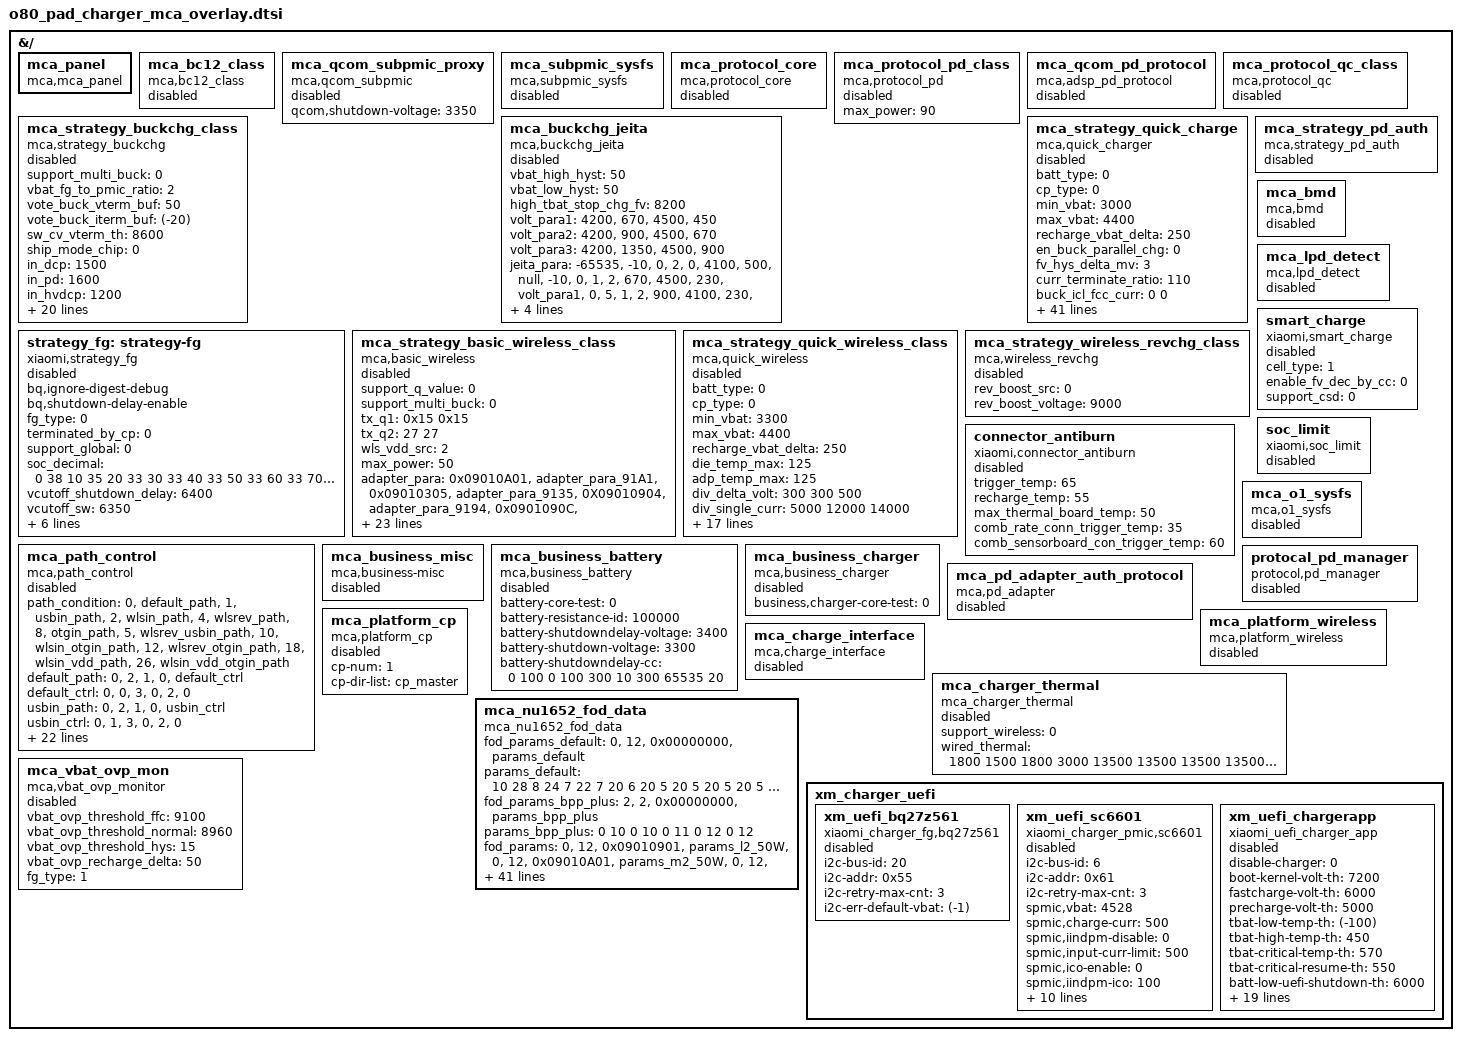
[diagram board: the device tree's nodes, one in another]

&{/} {
	/*	sc8585 dts
	sc8585_master@6e {
		compatible = "sc8585_master";
		status = "disabled";
		ic_role = <0>;
		reg = <0x6e>;
		cp-int= <&dw_gpio1 15 0>; //gpio47
		cp-nlpm-gpio = <&dw_gpio3 26 0>;//gpio 107
		pinctrl-names = "default";
		pinctrl-0 = <&gpio_047_default>,
					<&gpio_107_default>; //gpio107
		pinctrl-1 = <&gpio_212_default>; //212
		bat-ovp-threshold = <4650>;
		bat-ovp-alarm-threshold = <4600>;
		bus-ovp-threshold = <21000 11000 6000>;
		usb-ovp-threshold = <21000 14000 6500>;
		bus-ocp-threshold = <4500 5000 4500>;
		wpc-ovp-threshold = <21000>;
		out-ovp-threshold = <5000>;
		pmid2-uvp-threshold = <100>;
		pmid2-ovp-threshold = <600>;
	};

	// sc8577 dts
	sc8577@65 {
		compatible = "sc8577_master";
		status = "okay";
		ic_role = <0>;
		reg = <0x65>;
		cp-int= <&dw_gpio0 15 0>; //gpio15
		cp-nlpm-gpio = <&dw_gpio3 26 0>;//gpio 107
		pinctrl-names = "default";
		pinctrl-0 = <&gpio_015_default>,
					<&gpio_107_default>,
					<&gpio_212_default>; //gpio212	ovpmos gpio
		bat-ovp-threshold = <9300>;
		bat-ovp-alarm-threshold = <9200>;
		bus-ovp-threshold = <21000 11000>;
		usb-ovp-threshold = <21000 13000>;
		bus-ocp-threshold = <6000 6000>;
		wpc-ovp-threshold = <21000>;
		out-ovp-threshold = <10000>;
		pmid2-uvp-threshold = <100>;
		pmid2-ovp-threshold = <600>;
	};
	 */
	mca_panel: mca_panel {
		compatible = "mca,mca_panel";
		status = "okay";
	};

	mca_bc12_class: mca_bc12_class {
		compatible = "mca,bc12_class";
		status = "disabled";
	};

	mca_qcom_subpmic_proxy: mca_qcom_subpmic_proxy {
		compatible = "mca,qcom_subpmic";
		qcom,shutdown-voltage = <3350>;
		status = "disabled";
	};

	mca_subpmic_sysfs: mca_subpmic_sysfs {
		compatible = "mca,subpmic_sysfs";
		status = "disabled";
	};

	mca_protocol_core: mca_protocol_core {
		compatible = "mca,protocol_core";
		status = "disabled";
	};

	mca_protocol_pd_class: mca_protocol_pd_class {
		compatible = "mca,protocol_pd";
		status = "disabled";
		max_power = <90>;
	};

	mca_qcom_pd_protocol: mca_qcom_pd_protocol {
		compatible = "mca,adsp_pd_protocol";
		status = "disabled";
	};

	mca_protocol_qc_class: mca_protocol_qc_class {
		compatible = "mca,protocol_qc";
		status = "disabled";
	};

	mca_buckchg_jeita: mca_buckchg_jeita {
		compatible = "mca,buckchg_jeita";
		vbat_high_hyst = <50>;
		vbat_low_hyst = <50>;
		high_tbat_stop_chg_fv = <8200>;
		volt_para1 =
			"4200", "670",
			"4500", "450";
		volt_para2 =
			"4200", "900",
			"4500", "670";
		volt_para3 =
			"4200", "1350",
			"4500", "900";
		/* temp_low, temp_high, low_temp_hys, high_temp_hys, max_current, vterm, iterm volt_para_name */
		jeita_para =
			"-65535", "-10", "0", "2", "0", "4100", "500", "null",
			"-10", "0", "1", "2", "670", "4500", "230", "volt_para1",
			"0", "5", "1", "2", "900", "4100", "230", "volt_para2",
			"5", "10", "1", "2", "1350", "4500", "500", "volt_para3",
			"10", "48", "2", "2", "4000", "4500", "230", "null",
			"48", "60", "2", "2", "2250", "4100", "230", "null" ,
			"60", "65535", "2", "2", "0", "4100", "230", "null";

		status = "disabled";
	};

	mca_strategy_buckchg_class: mca_strategy_buckchg_class {
		compatible = "mca,strategy_buckchg";
		support_multi_buck = <0>;
		vbat_fg_to_pmic_ratio = <2>;
		vote_buck_vterm_buf = <50>;
		vote_buck_iterm_buf = <(-20)>;
		sw_cv_vterm_th = <8600>;
		ship_mode_chip = <0>;	/* 0:MAIN_BUCK_CHARGER, 1:AUX_BUCK_CHARGER  */
		in_dcp = <1500>;
		in_pd = <1600>;
		in_hvdcp = <1200>;
		in_hvdcp3 = <1600>;
		in_hvdcp3p5 = <1600>;
		in_cdp = <1000>;
		in_sdp = <500>;
		in_float = <1000>;
		chg_dcp = <2000>;
		chg_pd = <3000>;
		chg_hvdcp = <2600>;
		chg_hvdcp3 = <3600>;
		chg_hvdcp3p5 = <3600>;
		chg_cdp = <1000>;
		chg_sdp = <500>;
		chg_float = <1000>;
		chg_batt_auth_failed = <2000>;
		ffc_temp_low = <20>;
		ffc_temp_high = <48>;
		pmic_fv_compensation = <0>;

		//pps&pd_verify, other
		rev_req_vadp = <9000 9000>;
		rev_vadp_valid_h = <9200 9200>;
		rev_vadp_valid_l = <8400 8400>;

		status = "disabled";
	};


	mca_strategy_quick_charge: mca_strategy_quick_charge {
		compatible = "mca,quick_charger";
		status = "disabled";
		batt_type = <0>;
		cp_type = <0>;
		min_vbat = <3000>;
		max_vbat = <4400>;
		recharge_vbat_delta = <250>;
		en_buck_parallel_chg = <0>;
		fv_hys_delta_mv = <3>;
		curr_terminate_ratio = <110>;
		buck_icl_fcc_curr = <0 0>;
		die_temp_max = <125>;
		adp_temp_max = <125>;
		div_delta_volt = <300 300 500>;
		div_delta_ibat = <200 200 200>;
		div_single_curr = <5000 12000 14000>;
		div_max_curr = <5000 12000 14000>;
		multi_ibus_th = <2000 1500 600>;
		ibus_inc_hysteresis = <200 200 100>;
		ibus_dec_hysteresis = <200 200 100>;
		open_path_th = <800 600 400>;
		ibus_compensation = <0 0 0>;
		support_mode = <7>;
		max_power = <67000>;
		qc_normal_charge_fv = <4480>;
		qc3_max_vbus_limit = <9500>;
		qc3_max_ibus_limit = <2500>;
		qc3_ibat_max_limit = <5000>;
		qc3p5_max_vbus_limit = <10000>;
		qc3p5_max_ibus_limit = <2200>;
		qc3p5_ibat_max_limit = <4400>;
		qc_taper_fcc_thr = <2400>;
		pps_taper_fcc_thr = <2400>;
		qc3_taper_vol_hys = <25>;
		qc3p5_taper_vol_hys = <20>;
		pps_taper_vol_hys = <5>;

		support_cp_vfc = <0>;
		vfc_iout_fsw_map =
			"6000", "720",
			"0", "300";
		support_curr_monitor = <0>;
		curr_monitor_time_s = <0>;
		cp_switch_pmic_th = <1500>;

		batt_para =
			"0", "lwn", "temp_para1",
			"0", "atl", "temp_para1";
		/* temp_low, temp_high, low_temp_hys, high_temp_hys, max_current, volt_para_name stage_para_name*/
		temp_para1 =
			"-65535", "10", "0", "0", "0", "null", "null", "null", "null",
			"10", "48", "2", "2", "12000", "volt_para1", "volt_para1", "stage_para1", "stage_para1",
			"48", "65535", "0", "0", "0", "null", "null", "null", "null";
		volt_para1 =
			"4100", "12000", "10000",
			"4300", "10000", "6000",
			"4400", "6000", "1200";
		stage_para1 = <0 0 0 0 0 0>;
		vstep_para =
			"1", "2000", "2",
			"2", "2000", "4",
			"4", "4000", "8",
			"4", "2000", "4",
			"4", "1000", "2";
	};

	mca_strategy_pd_auth: mca_strategy_pd_auth {
		compatible = "mca,strategy_pd_auth";
		status = "disabled";
	};

	strategy_fg: strategy-fg {
		compatible = "xiaomi,strategy_fg";
		bq,ignore-digest-debug;
		bq,shutdown-delay-enable;
		fg_type = <0>;
		terminated_by_cp = <0>;
		support_global = <0>;
		soc_decimal = <
			0  38
			10 35
			20 33
			30 33
			40 33
			50 33
			60 33
			70 30
			80 25
			90 20
			95 10 >;
		vcutoff_shutdown_delay = <6400>;
		vcutoff_sw = <6350>;
		vcutoff_fw = <6350>;
		support_fl4p0 = <0>;
		fg_hightemp_vterm = <8400>;
		status = "disabled";
		extreme_cold_temp_compemsation =
			"100", "50", "50",
			"100", "150", "65",
			"350", "150", "80",
			"2147483647", "150", "100";
	};


	mca_strategy_basic_wireless_class: mca_strategy_basic_wireless_class {
		compatible = "mca,basic_wireless";
		support_q_value = <0>;
		support_multi_buck = <0>;
		//low_inductance_tx, standard_tx
		tx_q1 = /bits/ 8 <0x15 0x15>;
		tx_q2 = <27 27>;
		wls_vdd_src = <2>;
		status = "disabled";
		max_power = <50>;

		adapter_para =
			"0x09010A01", "adapter_para_91A1",	/* XIAOMI_TX_UUID_LOW_INDUCTANCE_50W */
			"0x09010305", "adapter_para_9135",	/* XIAOMI_TX_UUID_LOW_INDUCTANCE_80W */
			"0X09010904", "adapter_para_9194",	/* XIAOMI_TX_UUID_SAILBOAT_80W */
			"0x0901090C", "adapter_para_919C",	/* XIAOMI_TX_UUID_SAILBOAT_100W */
			"0x09010907", "adapter_para_9197",	/* XIAOMI_TX_UUID_REDMI_30W */
			"0x01010E01", "adapter_para_01E1",	/* XIAOMI_TX_UUID_TRAIN_20W */
			"0x01080205", "adapter_para_1825",	/* XIAOMI_TX_UUID_ZIMI_CAR_50W */
			"0x09080207", "adapter_para_9827",	/* XIAOMI_TX_UUID_ZIMI_CAR_30W */
			"0x06020801", "adapter_para_6281",	/* XIAOMI_TX_UUID_ZIMI_CAR_20W */
			"0x0C090908", "adapter_para_C998",	/* XIAOMI_TX_UUID_MULTI_COIL2_20W */
			"0x0C090906", "adapter_para_C996",	/* XIAOMI_TX_UUID_MULTI_COIL_20W */
			"0x09010506", "adapter_para_9156",	/* XIAOMI_TX_UUID_MOVING_PLATE_20W */
			"0x09080607", "adapter_para_9867";	/* XIAOMI_TX_UUID_MUSICAL_BOX_30W */

		/* standard_tx, musical_box, plate_tx, car_mounted, train_tx, redmi_30w_tx,sailboat_tx , low_inductance_50w_tx, low_inductance_80w_tx */
		adapter_para_91A1 = "1", "0", "0", "0", "0", "0", "0", "1", "0";
		adapter_para_9135 = "0", "0", "0", "0", "0", "0", "0", "0", "1";
		adapter_para_9194 = "0", "0", "0", "0", "0", "0", "1", "0", "0";
		adapter_para_919C = "0", "0", "0", "0", "0", "0", "1", "0", "0";
		adapter_para_9197 = "0", "0", "0", "0", "0", "1", "0", "0", "0";
		adapter_para_01E1 = "0", "0", "0", "0", "1", "0", "0", "0", "0";
		adapter_para_1825 = "0", "0", "0", "1", "0", "0", "0", "0", "0";
		adapter_para_9827 = "0", "0", "0", "1", "0", "0", "0", "0", "0";
		adapter_para_6281 = "0", "0", "0", "1", "0", "0", "0", "0", "0";
		adapter_para_C998 = "0", "0", "1", "0", "0", "0", "0", "0", "0";
		adapter_para_C996 = "0", "0", "1", "0", "0", "0", "0", "0", "0";
		adapter_para_9156 = "0", "0", "1", "0", "0", "0", "0", "0", "0";
		adapter_para_9867 = "0", "1", "0", "0", "0", "0", "0", "0", "0";

	};

	mca_strategy_quick_wireless_class: mca_strategy_quick_wireless_class {
		compatible = "mca,quick_wireless";
		status = "disabled";
		batt_type = <0>;
		cp_type = <0>;
		min_vbat = <3300>;
		max_vbat = <4400>;
		recharge_vbat_delta = <250>;
		die_temp_max = <125>;
		adp_temp_max = <125>;
		div_delta_volt = <300 300 500>;
		div_single_curr = <5000 12000 14000>;
		div_max_curr = <5000 12000 14000>;
		multi_ibus_th = <400 400 400>;
		ibus_inc_hysteresis = <100 100 100>;
		ibus_dec_hysteresis = <100 100 100>;
		open_path_th = <800 600 400>;
		support_mode = <4>;
		batt_para =
			"0", "lwn", "temp_para1",
			"0", "atl", "temp_para1";
		/* temp_low, temp_high, low_temp_hys, high_temp_hys, max_current, volt_para_name stage_para_name*/
		temp_para1 =
			"-65535", "10", "0", "0", "0", "null", "null", "null", "null",
			"10", "48", "2", "2", "12000", "volt_para1", "volt_para1", "stage_para1", "stage_para1",
			"48", "65535", "0", "0", "0", "null", "null", "null", "null";
		volt_para1 =
			"4100", "12000", "10000",
			"4300", "10000", "6000",
			"4400", "6000", "1200";
		stage_para1 = <0 0 0 0 0 0>;
		vstep_para =
			"1", "2000", "2",
			"2", "2000", "4",
			"4", "4000", "8",
			"4", "2000", "4";
	};

	mca_strategy_wireless_revchg_class: mca_strategy_wireless_revchg_class {
		compatible = "mca,wireless_revchg";
		status = "disabled";
		rev_boost_src = <0>;
		rev_boost_voltage = <9000>;
	};

	connector_antiburn: connector_antiburn {
		compatible = "xiaomi,connector_antiburn";
		status = "disabled";
		trigger_temp = <65>;
		recharge_temp = <55>;
		max_thermal_board_temp = <50>;
		comb_rate_conn_trigger_temp = <35>; //The connector trigger temperature combined with temperature increase rate.
		comb_sensorboard_con_trigger_temp = <60>; //The connector trigger temperature combined with temperature of thermal sensor board.
	};

	mca_bmd: mca_bmd {
		compatible = "mca,bmd";
		status = "disabled";
	};

	mca_path_control: mca_path_control {
		compatible = "mca,path_control";
		status = "disabled";
		path_condition =
			"0",  "default_path",	/* DEFAULT_CONDITION */
			"1",  "usbin_path",	/* USB_IN */
			"2",  "wlsin_path",	/* WIRELESS_IN */
			"4",  "wlsrev_path",	/* WIRELES_REV */
			"8",  "otgin_path",	/* OTG_IN */
			"5",  "wlsrev_usbin_path",	/* WIRELESS_REV_USB_IN */
			"10", "wlsin_otgin_path",	/* WIRELESS_IN_OTG_IN */
			"12", "wlsrev_otgin_path",	/* WIRELESS_REV_OTG_IN */
			"18", "wlsin_vdd_path",	/* WIRELESS_IN_VDD */
			"26", "wlsin_vdd_otgin_path";	/* WIRELESS_IN_VDD_IN_OTG_IN */
		/* src1, xxx_src, src2, yyy_src control_para */
		default_path =
			"0", "2", "1", "0", "default_ctrl";
		default_ctrl =
			"0", "0",
			"3", "0",
			"2", "0";
		usbin_path =
			"0", "2", "1", "0", "usbin_ctrl";
		/* control_gate_role, enable */
		usbin_ctrl =
			"0", "1",
			"3", "0",
			"2", "0";
		wlsin_path =
			"0", "2", "1", "0", "wlsin_ctrl";
		wlsin_ctrl =
			"0", "0",
			"3", "0",
			"2", "0";
		wlsrev_path =
			"0", "2", "1", "0", "wlsrev_ctrl";
		wlsrev_ctrl =
			"0", "0",
			"3", "0",
			"2", "0";
		otgin_path =
			"0", "2", "1", "0", "otgin_ctrl";
		otgin_ctrl =
			"0", "0",
			"3", "1",
			"2", "1";
		wlsrev_usbin_path =
			"0", "2", "1", "0", "wlsrev_usbin_ctrl";
		wlsrev_usbin_ctrl =
			"0", "1",
			"3", "0",
			"2", "0";
		wlsin_otgin_path =
			"0", "2", "1", "0", "wlsin_otgin_ctrl";
		wlsin_otgin_ctrl =
			"0", "0",
			"3", "1",
			"2", "1";
		wlsrev_otgin_path =
			"0", "2", "1", "0", "wlsrev_otgin_ctrl";
		wlsrev_otgin_ctrl =
			"0", "0",
			"3", "1",
			"2", "1";
		wlsin_vdd_path =
			"0", "2", "1", "0", "wlsin_vdd_ctrl";
		wlsin_vdd_ctrl =
			"0", "0",
			"3", "1",
			"2", "0";
		wlsin_vdd_otgin_path =
			"0", "2", "1", "0", "wlsin_vdd_otgin_ctrl";
		wlsin_vdd_otgin_ctrl =
			"0", "0",
			"3", "1",
			"2", "1";

		/* gate_type, control_scheme, process_way */
		/* gate_type: 0:ovpgate, 1:wpcgate, 2:ext_bst_gate,
						3:wireless_vdd_gate, 4:haptics_bst_gate */
		/* control_scheme: 0:GPIO 1:PMIC_REGISTER 2:CP_CHIP */
		control_scheme =
			"0", "2", "ovpgate,cp_chip_role",
			"1", "2", "null",
			"2", "0", "null",
			"3", "0", "null",
			"4", "0", "null";
		/* chip_project, chip_role */
		ovpgate,cp_chip_role = <0>;
	};

	mca_lpd_detect: mca_lpd_detect {
		compatible = "mca,lpd_detect";
		status = "disabled";
	};

	smart_charge: smart_charge {
		compatible = "xiaomi,smart_charge";
		cell_type = <1>;
		status = "disabled";
		enable_fv_dec_by_cc = <0>;
		support_csd = <0>;
	};

	soc_limit: soc_limit {
		compatible = "xiaomi,soc_limit";
		status = "disabled";
	};

	mca_o1_sysfs: mca_o1_sysfs {
		compatible = "mca,o1_sysfs";
		status = "disabled";
	};


	mca_business_misc: mca_business_misc {
		compatible = "mca,business-misc";
		status = "disabled";
	};

	mca_business_battery: mca_business_battery {
		compatible = "mca,business_battery";
		battery-core-test = <0>;
		battery-resistance-id = <100000>;
		battery-shutdowndelay-voltage = <3400>;
		battery-shutdown-voltage = <3300>;
		battery-shutdowndelay-cc = <
						0  100  0
						100   300   10
						300  65535  20>;
		status = "disabled";
	};

	mca_business_charger: mca_business_charger {
		compatible = "mca,business_charger";

		/* charger_core */
		business,charger-core-test = <0>;

		status = "disabled";
	};

	protocal_pd_manager: protocal_pd_manager {
		status = "disabled";
		#io-channel-cells = <1>;
		compatible = "protocol,pd_manager";
	};

	mca_pd_adapter_auth_protocol: mca_pd_adapter_auth_protocol {
		compatible = "mca,pd_adapter";
		status = "disabled";
	};

	mca_platform_cp: mca_platform_cp {
		compatible = "mca,platform_cp";
		status = "disabled";
		cp-num = <1>;
		cp-dir-list = "cp_master";
	};

	mca_platform_wireless: mca_platform_wireless {
		compatible = "mca,platform_wireless";
		status = "disabled";
	};

	mca_charge_interface: mca_charge_interface {
		compatible = "mca,charge_interface";
		status = "disabled";
	};

	mca_charger_thermal: mca_charger_thermal {
		compatible = "mca_charger_thermal";
		support_wireless = <0>;
		/* 5v_in 9v_in 5v_ichg 9v_ichg div1_single div1_multi div2_single div2_multi div4_single div4_multi*/
		wired_thermal = <
		1800 1500 1800 3000 13500 13500 13500 13500 13500 13500 /* level 1 */
		1800 1500 1800 3000 11000 11000 11000 11000 11000 11000 /* level 2 */
		1800 1500 1800 3000 9000  9000  9000  9000  9000  9000  /* level 3 */
		1800 1500 1800 3000 8000  8000  8000  8000  8000  8000  /* level 4 */
		1800 1500 1800 3000 7000  7000  7000  7000  7000  7000  /* level 5 */
		1800 1400 1800 2800 6000  6000  6000  6000  6000  6000  /* level 6 */
		1800 1300 1800 2600 5000  5000  5000  5000  5000  5000  /* level 7 */
		1800 1150 1800 2310 4000  4000  4000  4000  4000  4000  /* level 8 */
		1700 1100 1700 2200 3500  3500  3500  3500  3500  3500  /* level 9 */
		1600 1000 1600 2000 3000  3000  3000  3000  3000  3000  /* level 10 */
		1400 900  1400 1800 2500  2500  2500  2500  2500  2500  /* level 11 */
		1200 850  1200 1600 2000  2000  2000  2000  2000  2000  /* level 12 */
		1100 750  1100 1500 1500  1500  1500  1500  1500  1500  /* level 13 */
		1100 650  1100 1300 1000  1000  1000  1000  1000  1000  /* level 14 */
		1000 500  1000 1000 500   500   500   500   500   500   /* level 15 */
		>;
		status = "disabled";
	};

	mca_nu1652_fod_data: mca_nu1652_fod_data {
		compatible = "mca_nu1652_fod_data";

		fod_params_default =
			"0", "12", "0x00000000", "params_default";
		params_default = /bits/ 8 <
			10 28
			8  24
			7  22
			7  20
			6  20
			5  20
			5  20
			5  20
			5  20
			5  20
			4  20
			4  20
		>;

		fod_params_bpp_plus =
			"2", "2",  "0x00000000", "params_bpp_plus";
		params_bpp_plus = /bits/ 8 <
			0 10
			0 10
			0 11
			0 12
			0 12
		>;

		/* type, length, uuid, params */
		fod_params =
			"0", "12", "0x09010901", "params_l2_50W",
			"0", "12", "0x09010A01", "params_m2_50W",
			"0", "12", "0x09010904", "params_k1_80W",
			"0", "12", "0x0901090C", "params_k8_100W",
			"0", "12", "0x0901010B", "params_j1s_55W",
			"0", "12", "0x09010407", "params_white_stand_30W",
			"0", "12", "0x09080607", "params_bluetooth_30W",
			"0", "12", "0x09010506", "params_moving_20W",
			"0", "12", "0x09080108", "params_zimi_20W",
			"0", "12", "0x06010101", "params_white_20W",
			"0", "12", "0x07030801", "params_power_bank_30W",
			"0", "12", "0x06020801", "params_zimi_car_20W",
			"0", "12", "0x0C090906", "params_multcoil_20W",
			"0", "12", "0x0C090908", "params_multcoil_20W",
			"0", "12", "0x09010907", "params_redmi_disc_30W";
		/* gain, offset */
		params_l2_50W = /bits/ 8 <
			12 28
			12 26
			12 22
			10 16
			10 10
			8  8
			7  6
			6  4
			5  2
			4  2
			4  2
			4  2
		>;

		params_m2_50W = /bits/ 8 <
			12 20
			12 18
			12 16
			10 12
			8  6
			6  6
			4  4
			4  4
			3  4
			3  4
			3  2
			3  2
		>;

		params_k1_80W = /bits/ 8 <
			14 28
			14 18
			14 16
			12 12
			11 10
			10 10
			9  8
			8  8
			8  2
			7  0
			7  0
			7  0
		>;

		params_k8_100W = /bits/ 8 <
			14 28
			14 18
			14 16
			12 12
			12 12
			10 10
			9  10
			8  8
			7  4
			7  2
			7  2
			7  2
		>;

		params_j1s_55W = /bits/ 8 <
			12 28
			12 26
			12 22
			10 16
			10 10
			8  8
			7  6
			6  4
			5  2
			4  2
			4  2
			4  2
		>;

		params_white_stand_30W = /bits/ 8 <
			12 26
			12 18
			12 14
			12 10
			10 6
			9  4
			9  2
			9  2
			9  2
			9  2
			9  2
			9  2
		>;

		params_bluetooth_30W = /bits/ 8 <
			12 18
			12 18
			12 17
			10 15
			10 15
			8  13
			8  13
			8  13
			8  13
			8  13
			8  13
			8  13
		>;

		params_moving_20W = /bits/ 8 <
			10 20
			10 16
			10 10
			6  8
			6  4
			6  4
			6  4
			6  4
			6  4
			6  4
			6  4
			6  4
		>;

		params_zimi_20W = /bits/ 8 <
			12 20
			13 20
			13 20
			13 18
			12 12
			10 10
			10 10
			10 10
			10 10
			10 10
			10 10
			10 10
		>;

		params_white_20W = /bits/ 8 <
			10 24
			10 18
			10 18
			10 15
			10 15
			10 10
			10 10
			10 10
			10 10
			10 10
			10 10
			10 10
		>;

		params_power_bank_30W = /bits/ 8 <
			2  7
			2  7
			3  7
			6  11
			7  12
			8  13
			8  13
			8  13
			8  13
			8  13
			8  13
			8  13
		>;

		params_zimi_car_20W = /bits/ 8 <
			5  12
			5  12
			5  12
			5  10
			5  10
			5  8
			5  8
			5  8
			5  8
			5  8
			5  8
			5  8
		>;

		params_multcoil_20W = /bits/ 8 <
			10  16
			10  14
			10  14
			10  12
			10  12
			10  10
			10  10
			10  10
			10  10
			10  10
			10  10
			10  10
		>;

		params_redmi_disc_30W = /bits/ 8 <
			10 22
			10 15
			10 10
			10 6
			9  6
			9  4
			8  2
			8  2
			8  2
			8  2
			8  2
			8  2
		>;
	};

	mca_vbat_ovp_mon: mca_vbat_ovp_mon {
		compatible = "mca,vbat_ovp_monitor";
		vbat_ovp_threshold_ffc = <9100>;
		vbat_ovp_threshold_normal = <8960>;
		vbat_ovp_threshold_hys = <15>;
		vbat_ovp_recharge_delta = <50>;
		fg_type = <1>;
		status = "disabled";
	};

	xm_charger_uefi: xm_charger_uefi {
		xm_uefi_bq27z561: xm_uefi_bq27z561{
			compatible = "xiaomi_charger_fg,bq27z561";
			status = "disabled";
			i2c-bus-id = <20>;
			i2c-addr = <0x55>;
			i2c-retry-max-cnt = <3>;

			i2c-err-default-vbat = <(-1)>;	/* will directly try booting when vbat <= 500mA */
		};

		xm_uefi_sc6601: xm_uefi_sc6601 {
			compatible = "xiaomi_charger_pmic,sc6601";
			status = "disabled";
			i2c-bus-id = <6>;
			i2c-addr = <0x61>;
			i2c-retry-max-cnt = <3>;

			/* hw init */
			spmic,vbat = <4528>;
			spmic,charge-curr = <500>;
			spmic,iindpm-disable = <0>;
			spmic,input-curr-limit = <500>;
			spmic,ico-enable = <0>;
			spmic,iindpm-ico = <100>;
			spmic,precharge-volt = <1>;	/* 0:2900mv, 1:3000, 2:3100, 3:3200 */
			spmic,precharge-curr = <250>;
			spmic,vac_ovp = <6000>;
			spmic,vbus_ovp = <6000>;

			support-wireless-chg = <0>;

			cp,i2c-bus-id = <6>;
			cp,i2c-addr = <0x65>;
			cp,ovpgate-ovp-reg = <0x0E>;
			cp,ovpgate-ovp-val = <0x4C>;

			i2c-err-default-vbat = <(-1)>;	/* will directly try booting when vbat <= 500mA */
		};

		xm_uefi_chargerapp: xm_uefi_chargerapp {
			compatible = "xiaomi_uefi_charger_app";
			status = "disabled";
			disable-charger = <0>; /* 0: enable uefi charger app 1: disable */
			boot-kernel-volt-th = <7200>;
			fastcharge-volt-th = <6000>;
			precharge-volt-th = <5000>;
			tbat-low-temp-th = <(-100)>;	/* 0.1C */
			tbat-high-temp-th = <450>;	/* 0.1C */
			tbat-critical-temp-th = <570>;	/* 0.1C */
			tbat-critical-resume-th = <550>;
			batt-low-uefi-shutdown-th = <6000>;
			fg-pmic-vbat-ratio = <2>;	/* vbatfg/vbatpmic = 2*/
			high-soc-boot-volt-th = <6600>;

			precharge-curr-mA = <470>;

			sdp-aicl = <500>;
			sdp-ichg = <500>;
			cdp-aicl = <1500>;
			cdp-ichg = <1300>;
			dcp-aicl = <1500>;
			dcp-ichg = <1300>;
			hvdcp-aicl = <1300>;
			hvdcp-ichg = <2000>;

			support-zero-boot = <0>; /* 0: not supplort zero speed boot 1: support */
			sw-chgtype-volt-cfg = <3200 6800>, /* sdp */
				<3200 6800>, /* cdp */
				<3200 6800>, /* dcp */
				<3200 6800>, /* hvdcp */
				<3200 6800>; /* float */
			sw-jeita-cfg = <(-10) 0 956 6800>,
				<0 5 2390 6800>,
				<5 10 3000 6800>,
				<10 48 3000 6800>,
				<48 60 3000 6800>;
			sw-cycle-count-cfg = <0 100 6800>,
				<100 300 6800>,
				<300 800 6800>,
				<800 65535 6800>;
			};
	};
};
